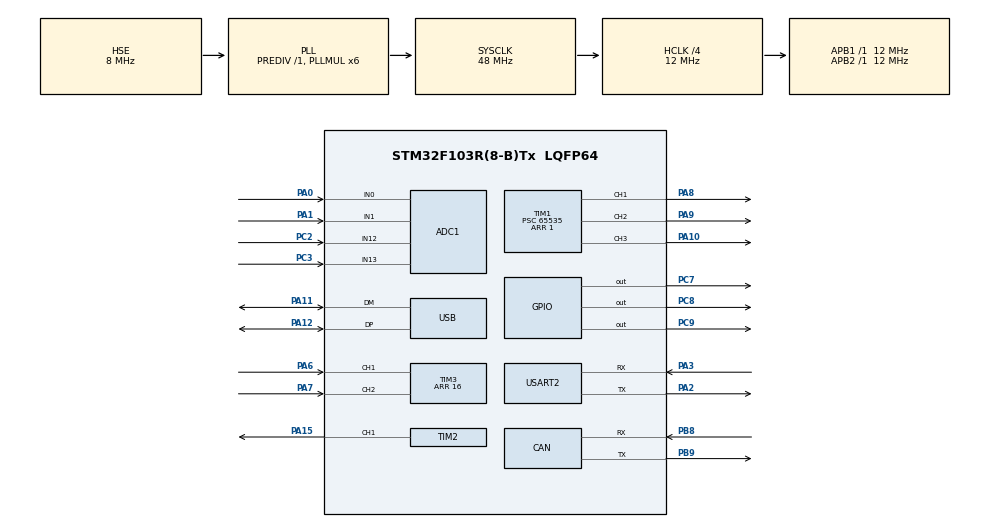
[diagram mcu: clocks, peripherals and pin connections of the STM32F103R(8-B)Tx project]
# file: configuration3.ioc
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ADC1.Channel-0\#ChannelRegularConversion=ADC_CHANNEL_0
ADC1.ContinuousConvMode=DISABLE
ADC1.DataAlign=ADC_DATAALIGN_RIGHT
ADC1.DiscontinuousConvMode=DISABLE
ADC1.EnableAnalogWatchDog=false
ADC1.EnableRegularConversion=ENABLE
ADC1.ExternalTrigConv=ADC_SOFTWARE_START
ADC1.InjNumberOfConversion=0
ADC1.NbrOfConversion=1
ADC1.NbrOfConversionFlag=1
ADC1.Rank-0\#ChannelRegularConversion=1
ADC1.SamplingTime-0\#ChannelRegularConversion=ADC_SAMPLETIME_1CYCLE_5
ADC1.ScanConvMode=ADC_SCAN_DISABLE
ADC1.master=1
CAN.CalculateTimeBit=1333
CAN.CalculateTimeQuantum=444.44444444444446
Mcu.Family=STM32F1
Mcu.Name=STM32F103R(8-B)Tx
Mcu.Package=LQFP64
NVIC.PriorityGroup=NVIC_PRIORITYGROUP_4
NVIC.USB_LP_CAN1_RX0_IRQn=true\:0\:0\:false\:false\:true\:false
PA0-WKUP.Signal=ADCx_IN0
PA1.Signal=ADCx_IN1
PA10.Signal=S_TIM1_CH3
PA11.Mode=Device
PA11.Signal=USB_DM
PA12.Mode=Device
PA12.Signal=USB_DP
PA15.Signal=S_TIM2_CH1_ETR
PA2.Mode=Asynchronous
PA2.Signal=USART2_TX
PA3.Mode=Asynchronous
PA3.Signal=USART2_RX
PA6.GPIO_PuPd=GPIO_PULLUP
PA6.Signal=S_TIM3_CH1
PA7.GPIO_PuPd=GPIO_PULLUP
PA7.Signal=S_TIM3_CH2
PA8.Signal=S_TIM1_CH1
PA9.Signal=S_TIM1_CH2
PB8.Mode=Master
PB8.Signal=CAN_RX
PB9.Mode=Master
PB9.Signal=CAN_TX
PC2.Signal=ADCx_IN12
PC3.Signal=ADCx_IN13
PC7.Signal=GPIO_Output
PC8.Signal=GPIO_Output
PC9.Signal=GPIO_Output
PD0-OSC_IN.Mode=HSE-External-Oscillator
PD0-OSC_IN.Signal=RCC_OSC_IN
PD1-OSC_OUT.Mode=HSE-External-Oscillator
PD1-OSC_OUT.Signal=RCC_OSC_OUT
ProjectManager.HeapSize=0x200
ProjectManager.StackSize=0x400
ProjectManager.TargetToolchain=MDK-ARM V5
RCC.ADCPresc=RCC_ADCPCLK2_DIV6
RCC.AHBCLKDivider=RCC_SYSCLK_DIV4
RCC.AHBFreq_Value=12000000
RCC.APB1Freq_Value=12000000
RCC.APB1TimFreq_Value=12000000
RCC.APB2Freq_Value=12000000
RCC.APB2TimFreq_Value=12000000
RCC.HCLKFreq_Value=12000000
RCC.PLLMUL=RCC_PLL_MUL6
RCC.SYSCLKFreq_VALUE=48000000
RCC.SYSCLKSource=RCC_SYSCLKSOURCE_PLLCLK
RCC.USBFreq_Value=48000000
SH.ADCx_IN0.0=ADC1_IN0,IN0
SH.ADCx_IN1.0=ADC1_IN1,IN1
SH.ADCx_IN12.0=ADC1_IN12,IN12
SH.ADCx_IN13.0=ADC1_IN13,IN13
SH.S_TIM1_CH1.0=TIM1_CH1,Forced Output1 CH1
SH.S_TIM1_CH2.0=TIM1_CH2,Forced Output2 CH2
SH.S_TIM1_CH3.0=TIM1_CH3,Forced Output3 CH3
SH.S_TIM2_CH1_ETR.0=TIM2_CH1,PWM Generation1 CH1
SH.S_TIM3_CH1.0=TIM3_CH1,Encoder_Interface
SH.S_TIM3_CH2.0=TIM3_CH2,Encoder_Interface
TIM1.Channel-Forced\ Output1\ CH1=TIM_CHANNEL_1
TIM1.Channel-Forced\ Output2\ CH2=TIM_CHANNEL_2
TIM1.Channel-Forced\ Output3\ CH3=TIM_CHANNEL_3
TIM1.ClockDivision=TIM_CLOCKDIVISION_DIV4
TIM1.Period=1
TIM1.Prescaler=65535
TIM1.RepetitionCounter=183
TIM2.Channel-PWM\ Generation1\ CH1=TIM_CHANNEL_1
TIM2.Period=6818
TIM3.Period=16
USART2.VirtualMode=VM_ASYNC
USB_DEVICE.CLASS_NAME_FS=DFU
USB_DEVICE.VirtualMode=Dfu
USB_DEVICE.VirtualModeFS=Dfu_FS
VP_SYS_VS_ND.Mode=No_Debug
VP_TIM1_VS_ClockSourceITR.Mode=TriggerSource_ITR0
VP_TIM1_VS_ControllerModeClock.Mode=Clock Mode
VP_TIM2_VS_ClockSourceITR.Mode=TriggerSource_ITR0
VP_TIM2_VS_ControllerModeClock.Mode=Clock Mode
VP_USB_DEVICE_VS_USB_DEVICE_DFU_FS.Mode=DFU_FS
board=configuration3

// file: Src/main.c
/**
  ******************************************************************************
  * @file           : main.c
  * @brief          : Main program body
  ******************************************************************************
  * This notice applies to any and all portions of this file
  * that are not between comment pairs USER CODE BEGIN and
  * USER CODE END. Other portions of this file, whether
  * inserted by the user or by software development tools
  * are owned by their respective copyright owners.
  *
  * Copyright (c) 2018 STMicroelectronics International N.V.
  * All rights reserved.
  *
  * Redistribution and use in source and binary forms, with or without
  * modification, are permitted, provided that the following conditions are met:
  *
  * 1. Redistribution of source code must retain the above copyright notice,
  *    this list of conditions and the following disclaimer.
  * 2. Redistributions in binary form must reproduce the above copyright notice,
  *    this list of conditions and the following disclaimer in the documentation
  *    and/or other materials provided with the distribution.
  * 3. Neither the name of STMicroelectronics nor the names of other
  *    contributors to this software may be used to endorse or promote products
  *    derived from this software without specific written permission.
  * 4. This software, including modifications and/or derivative works of this
  *    software, must execute solely and exclusively on microcontroller or
  *    microprocessor devices manufactured by or for STMicroelectronics.
  * 5. Redistribution and use of this software other than as permitted under
  *    this license is void and will automatically terminate your rights under
  *    this license.
  *
  * THIS SOFTWARE IS PROVIDED BY STMICROELECTRONICS AND CONTRIBUTORS "AS IS"
  * AND ANY EXPRESS, IMPLIED OR STATUTORY WARRANTIES, INCLUDING, BUT NOT
  * LIMITED TO, THE IMPLIED WARRANTIES OF MERCHANTABILITY, FITNESS FOR A
  * PARTICULAR PURPOSE AND NON-INFRINGEMENT OF THIRD PARTY INTELLECTUAL PROPERTY
  * RIGHTS ARE DISCLAIMED TO THE FULLEST EXTENT PERMITTED BY LAW. IN NO EVENT
  * SHALL STMICROELECTRONICS OR CONTRIBUTORS BE LIABLE FOR ANY DIRECT, INDIRECT,
  * INCIDENTAL, SPECIAL, EXEMPLARY, OR CONSEQUENTIAL DAMAGES (INCLUDING, BUT NOT
  * LIMITED TO, PROCUREMENT OF SUBSTITUTE GOODS OR SERVICES; LOSS OF USE, DATA,
  * OR PROFITS; OR BUSINESS INTERRUPTION) HOWEVER CAUSED AND ON ANY THEORY OF
  * LIABILITY, WHETHER IN CONTRACT, STRICT LIABILITY, OR TORT (INCLUDING
  * NEGLIGENCE OR OTHERWISE) ARISING IN ANY WAY OUT OF THE USE OF THIS SOFTWARE,
  * EVEN IF ADVISED OF THE POSSIBILITY OF SUCH DAMAGE.
  *
  ******************************************************************************
  */
#include "main.h"
#include "stm32f1xx_hal.h"
#include "usb_device.h"

/* USER CODE BEGIN Includes */
int i=0;
/* USER CODE END Includes */

ADC_HandleTypeDef hadc1;

CAN_HandleTypeDef hcan;

TIM_HandleTypeDef htim1;
TIM_HandleTypeDef htim2;
TIM_HandleTypeDef htim3;

UART_HandleTypeDef huart2;

/* USER CODE BEGIN PV */
/* Private variables ---------------------------------------------------------*/

/* USER CODE END PV */

void SystemClock_Config(void);
static void MX_GPIO_Init(void);
static void MX_ADC1_Init(void);
static void MX_CAN_Init(void);
static void MX_TIM1_Init(void);
static void MX_TIM2_Init(void);
static void MX_TIM3_Init(void);
static void MX_USART2_UART_Init(void);

void HAL_TIM_MspPostInit(TIM_HandleTypeDef *htim);

/* USER CODE BEGIN PFP */
/* Private function prototypes -----------------------------------------------*/
#if __GNUC__
	#define PUTCHAR_PROTOTYPE int _io_putchar(int ch)
#else
	#define PUTCHAR_PROTOTYPE int fputc(int ch, FILE *f)
#endif
/* USER CODE END PFP */

/* USER CODE BEGIN 0 */
PUTCHAR_PROTOTYPE
	{
	HAL_UART_Transmit(&huart2, (uint8_t *)&ch, 1, 0xFFFF);
	return ch;
}
/* USER CODE END PFP */

/* USER CODE BEGIN 0 */

/* USER CODE END 0 */

int main(void)
{

  /* MCU Configuration----------------------------------------------------------*/

  /* Reset of all peripherals, Initializes the Flash interface and the Systick. */
  HAL_Init();

  /* Configure the system clock */
  SystemClock_Config();

  /* Initialize all configured peripherals */
  MX_GPIO_Init();
  MX_ADC1_Init();
  MX_CAN_Init();
  MX_TIM1_Init();
  MX_TIM2_Init();
  MX_TIM3_Init();
  MX_USB_DEVICE_Init();
  MX_USART2_UART_Init();
  /* USER CODE BEGIN 2 */
HAL_TIM_Encoder_Start(&htim3,TIM_CHANNEL_ALL);
  /* USER CODE END 2 */
float num;
  /* Infinite loop */
  /* USER CODE BEGIN WHILE */
  while (1)
  {

 i=TIM3->CNT;
	num=i;
  /* USER CODE END WHILE */
printf("the counter is %d\n",i);
		printf("the rpm is %.2f\n",num/5.88235);
		HAL_Delay(1000);
		printf("the torque is %.2f NM\n",num/74.074);
		//coversion is:  4 turns to reach 10k max for pulses/ conversion is 10k/135NM(max motor torque)

  }

}

void SystemClock_Config(void)
{

  RCC_OscInitTypeDef RCC_OscInitStruct;
  RCC_ClkInitTypeDef RCC_ClkInitStruct;
  RCC_PeriphCLKInitTypeDef PeriphClkInit;

    /**Initializes the CPU, AHB and APB busses clocks
    */
  RCC_OscInitStruct.OscillatorType = RCC_OSCILLATORTYPE_HSE;
  RCC_OscInitStruct.HSEState = RCC_HSE_ON;
  RCC_OscInitStruct.HSEPredivValue = RCC_HSE_PREDIV_DIV1;
  RCC_OscInitStruct.HSIState = RCC_HSI_ON;
  RCC_OscInitStruct.PLL.PLLState = RCC_PLL_ON;
  RCC_OscInitStruct.PLL.PLLSource = RCC_PLLSOURCE_HSE;
  RCC_OscInitStruct.PLL.PLLMUL = RCC_PLL_MUL6;
  if (HAL_RCC_OscConfig(&RCC_OscInitStruct) != HAL_OK)
  {
    _Error_Handler(__FILE__, __LINE__);
  }

    /**Initializes the CPU, AHB and APB busses clocks
    */
  RCC_ClkInitStruct.ClockType = RCC_CLOCKTYPE_HCLK|RCC_CLOCKTYPE_SYSCLK
                              |RCC_CLOCKTYPE_PCLK1|RCC_CLOCKTYPE_PCLK2;
  RCC_ClkInitStruct.SYSCLKSource = RCC_SYSCLKSOURCE_PLLCLK;
  RCC_ClkInitStruct.AHBCLKDivider = RCC_SYSCLK_DIV4;
  RCC_ClkInitStruct.APB1CLKDivider = RCC_HCLK_DIV1;
  RCC_ClkInitStruct.APB2CLKDivider = RCC_HCLK_DIV1;

  if (HAL_RCC_ClockConfig(&RCC_ClkInitStruct, FLASH_LATENCY_1) != HAL_OK)
  {
    _Error_Handler(__FILE__, __LINE__);
  }

  PeriphClkInit.PeriphClockSelection = RCC_PERIPHCLK_ADC|RCC_PERIPHCLK_USB;
  PeriphClkInit.AdcClockSelection = RCC_ADCPCLK2_DIV6;
  PeriphClkInit.UsbClockSelection = RCC_USBCLKSOURCE_PLL;
  if (HAL_RCCEx_PeriphCLKConfig(&PeriphClkInit) != HAL_OK)
  {
    _Error_Handler(__FILE__, __LINE__);
  }

    /**Configure the Systick interrupt time
    */
  HAL_SYSTICK_Config(HAL_RCC_GetHCLKFreq()/1000);

    /**Configure the Systick
    */
  HAL_SYSTICK_CLKSourceConfig(SYSTICK_CLKSOURCE_HCLK);

  /* SysTick_IRQn interrupt configuration */
  HAL_NVIC_SetPriority(SysTick_IRQn, 0, 0);
}

/* ADC1 init function */
static void MX_ADC1_Init(void)
{

  ADC_ChannelConfTypeDef sConfig;

    /**Common config
    */
  hadc1.Instance = ADC1;
  hadc1.Init.ScanConvMode = ADC_SCAN_DISABLE;
  hadc1.Init.ContinuousConvMode = DISABLE;
  hadc1.Init.DiscontinuousConvMode = DISABLE;
  hadc1.Init.ExternalTrigConv = ADC_SOFTWARE_START;
  hadc1.Init.DataAlign = ADC_DATAALIGN_RIGHT;
  hadc1.Init.NbrOfConversion = 1;
  if (HAL_ADC_Init(&hadc1) != HAL_OK)
  {
    _Error_Handler(__FILE__, __LINE__);
  }

    /**Configure Regular Channel
    */
  sConfig.Channel = ADC_CHANNEL_0;
  sConfig.Rank = ADC_REGULAR_RANK_1;
  sConfig.SamplingTime = ADC_SAMPLETIME_1CYCLE_5;
  if (HAL_ADC_ConfigChannel(&hadc1, &sConfig) != HAL_OK)
  {
    _Error_Handler(__FILE__, __LINE__);
  }

}

/* CAN init function */
static void MX_CAN_Init(void)
{

  hcan.Instance = CAN1;
  hcan.Init.Prescaler = 16;
  hcan.Init.Mode = CAN_MODE_NORMAL;
  hcan.Init.SJW = CAN_SJW_1TQ;
  hcan.Init.BS1 = CAN_BS1_1TQ;
  hcan.Init.BS2 = CAN_BS2_1TQ;
  hcan.Init.TTCM = DISABLE;
  hcan.Init.ABOM = DISABLE;
  hcan.Init.AWUM = DISABLE;
  hcan.Init.NART = DISABLE;
  hcan.Init.RFLM = DISABLE;
  hcan.Init.TXFP = DISABLE;
  if (HAL_CAN_Init(&hcan) != HAL_OK)
  {
    _Error_Handler(__FILE__, __LINE__);
  }

}

/* TIM1 init function */
static void MX_TIM1_Init(void)
{

  TIM_SlaveConfigTypeDef sSlaveConfig;
  TIM_MasterConfigTypeDef sMasterConfig;
  TIM_OC_InitTypeDef sConfigOC;
  TIM_BreakDeadTimeConfigTypeDef sBreakDeadTimeConfig;

  htim1.Instance = TIM1;
  htim1.Init.Prescaler = 65535;
  htim1.Init.CounterMode = TIM_COUNTERMODE_UP;
  htim1.Init.Period = 1;
  htim1.Init.ClockDivision = TIM_CLOCKDIVISION_DIV4;
  htim1.Init.RepetitionCounter = 183;
  htim1.Init.AutoReloadPreload = TIM_AUTORELOAD_PRELOAD_DISABLE;
  if (HAL_TIM_Base_Init(&htim1) != HAL_OK)
  {
    _Error_Handler(__FILE__, __LINE__);
  }

  if (HAL_TIM_OC_Init(&htim1) != HAL_OK)
  {
    _Error_Handler(__FILE__, __LINE__);
  }

  sSlaveConfig.SlaveMode = TIM_SLAVEMODE_EXTERNAL1;
  sSlaveConfig.InputTrigger = TIM_TS_ITR0;
  if (HAL_TIM_SlaveConfigSynchronization(&htim1, &sSlaveConfig) != HAL_OK)
  {
    _Error_Handler(__FILE__, __LINE__);
  }

  sMasterConfig.MasterOutputTrigger = TIM_TRGO_RESET;
  sMasterConfig.MasterSlaveMode = TIM_MASTERSLAVEMODE_DISABLE;
  if (HAL_TIMEx_MasterConfigSynchronization(&htim1, &sMasterConfig) != HAL_OK)
  {
    _Error_Handler(__FILE__, __LINE__);
  }

  sConfigOC.OCMode = TIM_OCMODE_FORCED_ACTIVE;
  sConfigOC.Pulse = 0;
  sConfigOC.OCPolarity = TIM_OCPOLARITY_HIGH;
  sConfigOC.OCNPolarity = TIM_OCNPOLARITY_HIGH;
  sConfigOC.OCFastMode = TIM_OCFAST_DISABLE;
  sConfigOC.OCIdleState = TIM_OCIDLESTATE_RESET;
  sConfigOC.OCNIdleState = TIM_OCNIDLESTATE_RESET;
  if (HAL_TIM_OC_ConfigChannel(&htim1, &sConfigOC, TIM_CHANNEL_1) != HAL_OK)
  {
    _Error_Handler(__FILE__, __LINE__);
  }

  if (HAL_TIM_OC_ConfigChannel(&htim1, &sConfigOC, TIM_CHANNEL_2) != HAL_OK)
  {
    _Error_Handler(__FILE__, __LINE__);
  }

  if (HAL_TIM_OC_ConfigChannel(&htim1, &sConfigOC, TIM_CHANNEL_3) != HAL_OK)
  {
    _Error_Handler(__FILE__, __LINE__);
  }

  sBreakDeadTimeConfig.OffStateRunMode = TIM_OSSR_DISABLE;
  sBreakDeadTimeConfig.OffStateIDLEMode = TIM_OSSI_DISABLE;
  sBreakDeadTimeConfig.LockLevel = TIM_LOCKLEVEL_OFF;
  sBreakDeadTimeConfig.DeadTime = 0;
  sBreakDeadTimeConfig.BreakState = TIM_BREAK_DISABLE;
  sBreakDeadTimeConfig.BreakPolarity = TIM_BREAKPOLARITY_HIGH;
  sBreakDeadTimeConfig.AutomaticOutput = TIM_AUTOMATICOUTPUT_DISABLE;
  if (HAL_TIMEx_ConfigBreakDeadTime(&htim1, &sBreakDeadTimeConfig) != HAL_OK)
  {
    _Error_Handler(__FILE__, __LINE__);
  }

  HAL_TIM_MspPostInit(&htim1);

}

/* TIM2 init function */
static void MX_TIM2_Init(void)
{

  TIM_SlaveConfigTypeDef sSlaveConfig;
  TIM_MasterConfigTypeDef sMasterConfig;
  TIM_OC_InitTypeDef sConfigOC;

  htim2.Instance = TIM2;
  htim2.Init.Prescaler = 0;
  htim2.Init.CounterMode = TIM_COUNTERMODE_UP;
  htim2.Init.Period = 6818;
  htim2.Init.ClockDivision = TIM_CLOCKDIVISION_DIV1;
  htim2.Init.AutoReloadPreload = TIM_AUTORELOAD_PRELOAD_DISABLE;
  if (HAL_TIM_Base_Init(&htim2) != HAL_OK)
  {
    _Error_Handler(__FILE__, __LINE__);
  }

  if (HAL_TIM_PWM_Init(&htim2) != HAL_OK)
  {
    _Error_Handler(__FILE__, __LINE__);
  }

  sSlaveConfig.SlaveMode = TIM_SLAVEMODE_EXTERNAL1;
  sSlaveConfig.InputTrigger = TIM_TS_ITR0;
  if (HAL_TIM_SlaveConfigSynchronization(&htim2, &sSlaveConfig) != HAL_OK)
  {
    _Error_Handler(__FILE__, __LINE__);
  }

  sMasterConfig.MasterOutputTrigger = TIM_TRGO_RESET;
  sMasterConfig.MasterSlaveMode = TIM_MASTERSLAVEMODE_DISABLE;
  if (HAL_TIMEx_MasterConfigSynchronization(&htim2, &sMasterConfig) != HAL_OK)
  {
    _Error_Handler(__FILE__, __LINE__);
  }

  sConfigOC.OCMode = TIM_OCMODE_PWM1;
  sConfigOC.Pulse = 0;
  sConfigOC.OCPolarity = TIM_OCPOLARITY_HIGH;
  sConfigOC.OCFastMode = TIM_OCFAST_DISABLE;
  if (HAL_TIM_PWM_ConfigChannel(&htim2, &sConfigOC, TIM_CHANNEL_1) != HAL_OK)
  {
    _Error_Handler(__FILE__, __LINE__);
  }

  HAL_TIM_MspPostInit(&htim2);

}

/* TIM3 init function */
static void MX_TIM3_Init(void)
{

  TIM_Encoder_InitTypeDef sConfig;
  TIM_MasterConfigTypeDef sMasterConfig;

  htim3.Instance = TIM3;
  htim3.Init.Prescaler = 0;
  htim3.Init.CounterMode = TIM_COUNTERMODE_UP;
  htim3.Init.Period = 10000;
  htim3.Init.ClockDivision = TIM_CLOCKDIVISION_DIV1;
  htim3.Init.AutoReloadPreload = TIM_AUTORELOAD_PRELOAD_DISABLE;
  sConfig.EncoderMode = TIM_ENCODERMODE_TI1;
  sConfig.IC1Polarity = TIM_ICPOLARITY_RISING;
  sConfig.IC1Selection = TIM_ICSELECTION_DIRECTTI;
  sConfig.IC1Prescaler = TIM_ICPSC_DIV1;
  sConfig.IC1Filter = 0;
  sConfig.IC2Polarity = TIM_ICPOLARITY_RISING;
  sConfig.IC2Selection = TIM_ICSELECTION_DIRECTTI;
  sConfig.IC2Prescaler = TIM_ICPSC_DIV1;
  sConfig.IC2Filter = 0;
  if (HAL_TIM_Encoder_Init(&htim3, &sConfig) != HAL_OK)
  {
    _Error_Handler(__FILE__, __LINE__);
  }

  sMasterConfig.MasterOutputTrigger = TIM_TRGO_RESET;
  sMasterConfig.MasterSlaveMode = TIM_MASTERSLAVEMODE_DISABLE;
  if (HAL_TIMEx_MasterConfigSynchronization(&htim3, &sMasterConfig) != HAL_OK)
  {
    _Error_Handler(__FILE__, __LINE__);
  }

}

/* USART2 init function */
static void MX_USART2_UART_Init(void)
{

  huart2.Instance = USART2;
  huart2.Init.BaudRate = 115200;
  huart2.Init.WordLength = UART_WORDLENGTH_8B;
  huart2.Init.StopBits = UART_STOPBITS_1;
  huart2.Init.Parity = UART_PARITY_NONE;
  huart2.Init.Mode = UART_MODE_TX_RX;
  huart2.Init.HwFlowCtl = UART_HWCONTROL_NONE;
  huart2.Init.OverSampling = UART_OVERSAMPLING_16;
  if (HAL_UART_Init(&huart2) != HAL_OK)
  {
    _Error_Handler(__FILE__, __LINE__);
  }

}

/** Configure pins as
        * Analog
        * Input
        * Output
        * EVENT_OUT
        * EXTI
*/
static void MX_GPIO_Init(void)
{

  GPIO_InitTypeDef GPIO_InitStruct;

  /* GPIO Ports Clock Enable */
  __HAL_RCC_GPIOD_CLK_ENABLE();
  __HAL_RCC_GPIOC_CLK_ENABLE();
  __HAL_RCC_GPIOA_CLK_ENABLE();
  __HAL_RCC_GPIOB_CLK_ENABLE();

  /*Configure GPIO pin Output Level */
  HAL_GPIO_WritePin(GPIOC, GPIO_PIN_7|GPIO_PIN_8|GPIO_PIN_9, GPIO_PIN_RESET);

  /*Configure GPIO pins : PC7 PC8 PC9 */
  GPIO_InitStruct.Pin = GPIO_PIN_7|GPIO_PIN_8|GPIO_PIN_9;
  GPIO_InitStruct.Mode = GPIO_MODE_OUTPUT_PP;
  GPIO_InitStruct.Speed = GPIO_SPEED_FREQ_LOW;
  HAL_GPIO_Init(GPIOC, &GPIO_InitStruct);

}

void _Error_Handler(char *file, int line)
{
  while(1)
  {
  }
}

/************************ (C) COPYRIGHT STMicroelectronics *****END OF FILE****/
